AUTOSAR XML (schema 4-3-0)
package /ComponentTypes
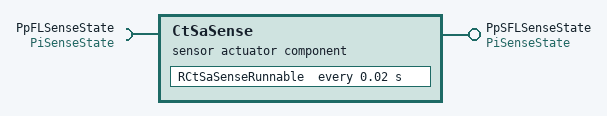
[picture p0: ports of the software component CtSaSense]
  sensor actuator sw component type CtSaSense
    require port PpFLSenseState: nonqueued-receiver-com-spec{data-element=DePiSenseState, filter=data-filter-type=ALWAYS, init-value=0}, required-interface=PiSenseState
    provide port PpSFLSenseState: nonqueued-sender-com-spec{data-element=DePiSenseState, init-value=0}, provided-interface=PiSenseState
    behavior CtSaSense_InternalBehavior
      timing event TMT_Runnable: start-on-event=RCtSaSenseRunnable, period=0.02
      runnable RCtSaSenseRunnable
        data-receive-point-by-arguments:
          access REC_PpFLSenseState_DePiSenseState: accessed-variable=PpFLSenseState.DePiSenseState
        data-send-points:
          access SEND_PpSFLSenseState_DePiSenseState: accessed-variable=PpSFLSenseState.DePiSenseState
  swc implementation CtSaSense_Implementation: behavior=CtSaSense_InternalBehavior
